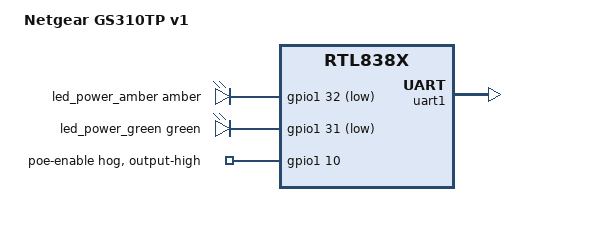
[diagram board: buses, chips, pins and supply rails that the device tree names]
// SPDX-License-Identifier: GPL-2.0-or-later

#include "rtl8380_netgear_gigabit.dtsi"

#include <dt-bindings/leds/common.h>

/ {
	compatible = "netgear,gs310tp-v1", "realtek,rtl838x-soc";
	model = "Netgear GS310TP v1";

	aliases {
		led-boot = &led_power_green;
		led-failsafe = &led_power_amber;
		led-running = &led_power_green;
		led-upgrade = &led_power_amber;
	};

	leds {
		compatible = "gpio-leds";

		led_power_amber: led-0 {
			color = <LED_COLOR_ID_AMBER>;
			function = LED_FUNCTION_POWER;
			gpios = <&gpio1 32 GPIO_ACTIVE_LOW>;
		};

		led_power_green: led-1 {
			color = <LED_COLOR_ID_GREEN>;
			function = LED_FUNCTION_POWER;
			gpios = <&gpio1 31 GPIO_ACTIVE_LOW>;
		};
	};
};

&gpio1 {
	poe-enable {
		gpio-hog;
		gpios = <10 GPIO_ACTIVE_HIGH>;
		output-high;
		line-name = "poe-enable";
	};
};

&firmware {
	openwrt,ih-magic = <0x4e474335>;
};

&uart1 {
	status = "okay";
};

&switch0 {
	ethernet-ports {
		/* TODO: fixed link SFP is not right */

		port24: port@24 {
			reg = <24>;
			label = SWITCH_PORT_LABEL(9);
			pcs-handle = <&serdes4 0>;
			phy-mode = "1000base-x";
			fixed-link {
				speed = <1000>;
				full-duplex;
			};
		};
		port26: port@26 {
			reg = <26>;
			label = SWITCH_PORT_LABEL(10);
			pcs-handle = <&serdes5 0>;
			phy-mode = "1000base-x";
			fixed-link {
				speed = <1000>;
				full-duplex;
			};
		};
	};
};
